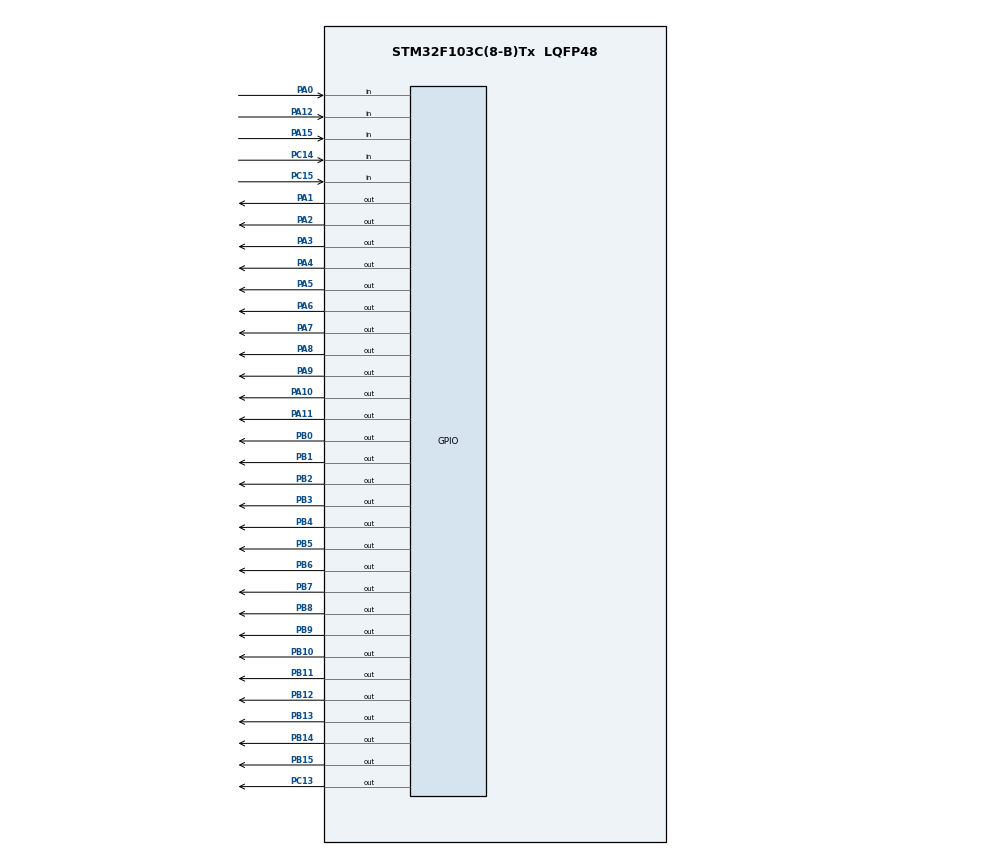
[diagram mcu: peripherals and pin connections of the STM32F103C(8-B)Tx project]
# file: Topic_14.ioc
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Mcu.Family=STM32F1
Mcu.Name=STM32F103C(8-B)Tx
Mcu.Package=LQFP48
NVIC.PriorityGroup=NVIC_PRIORITYGROUP_4
PA0-WKUP.GPIO_PuPd=GPIO_PULLUP
PA0-WKUP.Signal=GPIO_Input
PA1.Signal=GPIO_Output
PA10.Signal=GPIO_Output
PA11.Signal=GPIO_Output
PA12.GPIO_PuPd=GPIO_PULLUP
PA12.Signal=GPIO_Input
PA13.Mode=Serial_Wire
PA13.Signal=SYS_JTMS-SWDIO
PA14.Mode=Serial_Wire
PA14.Signal=SYS_JTCK-SWCLK
PA15.GPIO_PuPd=GPIO_PULLUP
PA15.Signal=GPIO_Input
PA2.Signal=GPIO_Output
PA3.Signal=GPIO_Output
PA4.Signal=GPIO_Output
PA5.Signal=GPIO_Output
PA6.Signal=GPIO_Output
PA7.Signal=GPIO_Output
PA8.Signal=GPIO_Output
PA9.Signal=GPIO_Output
PB0.Signal=GPIO_Output
PB1.Signal=GPIO_Output
PB10.Signal=GPIO_Output
PB11.Signal=GPIO_Output
PB12.GPIO_PuPd=GPIO_NOPULL
PB12.Signal=GPIO_Output
PB13.Signal=GPIO_Output
PB14.Signal=GPIO_Output
PB15.GPIO_PuPd=GPIO_NOPULL
PB15.Signal=GPIO_Output
PB2.Signal=GPIO_Output
PB3.Signal=GPIO_Output
PB4.Signal=GPIO_Output
PB5.Signal=GPIO_Output
PB6.Signal=GPIO_Output
PB7.Signal=GPIO_Output
PB8.Signal=GPIO_Output
PB9.Signal=GPIO_Output
PC13-TAMPER-RTC.Signal=GPIO_Output
PC14-OSC32_IN.GPIO_PuPd=GPIO_PULLUP
PC14-OSC32_IN.Signal=GPIO_Input
PC15-OSC32_OUT.GPIO_PuPd=GPIO_PULLUP
PC15-OSC32_OUT.Signal=GPIO_Input
ProjectManager.HeapSize=0x200
ProjectManager.StackSize=0x400
ProjectManager.TargetToolchain=Other Toolchains (GPDSC)
RCC.APB1Freq_Value=8000000
RCC.APB2Freq_Value=8000000
board=custom

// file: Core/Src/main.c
/* USER CODE BEGIN Header */
/**
  ******************************************************************************
  * @file           : main.c
  * @brief          : Main program body
  ******************************************************************************
  * @attention
  *
  * <h2><center>&copy; Copyright (c) 2025 STMicroelectronics.
  * All rights reserved.</center></h2>
  *
  * This software component is licensed by ST under BSD 3-Clause license,
  * the "License"; You may not use this file except in compliance with the
  * License. You may obtain a copy of the License at:
  *                        opensource.org/licenses/BSD-3-Clause
  *
  ******************************************************************************
  */
/* USER CODE END Header */
#include "main.h"

void SystemClock_Config(void);
static void MX_GPIO_Init(void);

int main(void)
{

	/* MCU Configuration--------------------------------------------------------*/

	/* Reset of all peripherals, Initializes the Flash interface and the Systick. */
	HAL_Init();

	/* Configure the system clock */
	SystemClock_Config();

	/* Initialize all configured peripherals */
	MX_GPIO_Init();

	/* USER CODE BEGIN 2 */

	test(50); //Самоиндикация экрана

	Test_4_LED(50); //Самоиндикация 4 лампочек

	Test_12_LED(50); //Самоиндикация 12 лампочек

	// Число для помощи формирования 2-чного
	int64_t countNums = 0;
	// Число в 2-чном представление
	uint64_t binaryNums = 0;

	// 1-ый бит измененый
	uint8_t firstBit = 0;
	// 2-ой бит измененый
	uint8_t secondBit = 0;
	// 3-ий бит измененый
	uint8_t thirdBit = 0;
	// 4-ий бит измененый
	uint8_t fourthBit = 0;

	//Первое число в 16 ричном формате
	uint8_t firstNum = 0;
	//Второе число в 16 ричном формате
	uint8_t secondNum = 0;
	//Третье число в 16 ричном формате
	uint8_t thirdNum = 0;

	int time = 0; // Переменная для подсчёта времени удержания кнопки
	int mode = 0; // Режим работы: 0 - увеличение числа, 1 - уменьшение

	/* USER CODE END 2 */

	/* Infinite loop */
	/* USER CODE BEGIN WHILE */

	  // 1 отпущина 0 нажата
	while (1)
	{

		/* USER CODE END WHILE */

		print_number(&firstNum, &secondNum, &thirdNum);
		// Преобразования числа в три шестнадцатеричных разряда
		DecimalHexadecimal(countNums, &firstNum, &secondNum, &thirdNum);
		if (countNums == 999) {

			binaryNums = 111111111111;
		}
		// Обработка удержания кнопки BUTTON_0 для смены режима
		if (HAL_GPIO_ReadPin(GPIOA, BUTTON_0) == 0) {
			DecimalHexadecimal(countNums, &firstNum, &secondNum, &thirdNum);

			time = 0;
			while (HAL_GPIO_ReadPin(GPIOA, BUTTON_0) == 0) {
				print_number(&firstNum, &secondNum, &thirdNum);
				HAL_Delay(15); // Задержка для измерения времени удержания
				time++;
			}

			if (time * 20 > 2000) {

				// Если кнопка удерживалась более 2000 мс
				mode++;
				if (mode > 2) mode = 0;

				// Сброс битов при переходе в режим 2
				if (mode == 2) {
					firstBit = 0;
					secondBit = 0;
					thirdBit = 0;
					fourthBit = 0;
				}
			}
			else {
				// Короткое нажатие - обработка в зависимости от режима
				if (mode == 0) {
					// Режим 0: увеличение
					if (countNums >= 999)
						countNums = 0;
					else
						countNums++;
					SetBinNumber(&countNums, &binaryNums);
				}
				else if (mode == 1) {
					// Режим 1: уменьшение
					if (countNums <= 0)
						countNums = 999;
					else
						countNums--;

					SetBinNumber(&countNums, &binaryNums);
				}
				// В режиме 2 короткое нажатие BUTTON_0 не делает ничего
			}
		}

		// Обработка режима 2
		if (mode == 2) {

			// Вывод числа на экран
			print_number(&firstNum, &secondNum, &thirdNum);

			// Задаем 1 бит и зажигаем 1 лампачку с помощью BUTTON_1
			SetFirstBit(&firstBit);

			// Задаем 2 бит и зажигаем 2 лампачку с помощью BUTTON_2
			SetSeconsBit(&secondBit);

			// Задаем 3 бит и зажигаем 3 лампачку с помощью BUTTON_3
			SetThirdBit(&thirdBit);

			// Задаем 4 бит и зажигаем 4 лампачку с помощью BUTTON_4
			SetFourthBit(&fourthBit);

			if (HAL_GPIO_ReadPin(GPIOA, BUTTON_0) == 0)
			{
				HAL_Delay(5);

				if (HAL_GPIO_ReadPin(GPIOA, BUTTON_0) == 0)
				{
					HAL_Delay(5);
					//Гасим светодиоды
					HAL_GPIO_WritePin(GPIOB, S_0_1, GPIO_PIN_RESET);
					HAL_GPIO_WritePin(GPIOB, S_0_2, GPIO_PIN_RESET);
					HAL_GPIO_WritePin(GPIOB, S_0_3, GPIO_PIN_RESET);
					HAL_GPIO_WritePin(GPIOC, S_0_4, GPIO_PIN_RESET);

					// Формируем 4-битное число из заданных битов
					uint64_t newBits = (firstBit << 3) | (secondBit << 2) | (thirdBit << 1) | fourthBit;

					// Сдвигаем исходное число на 4 бита влево и добавляем новые биты  числу
					countNums = (countNums << 4) | newBits;

					//Формируем в переменную binaryNums битную последовательность
					SetBinNumber(&countNums, &binaryNums);

					//Обнуляем заданные биты
					firstBit = 0;
					secondBit = 0;
					thirdBit = 0;
					fourthBit = 0;

					//Обновляем число в зависеммости от 2-чного
					countNums = Binary_to_Decimal(&binaryNums);

					// Преобразования числа в три шестнадцатеричных разряда
					DecimalHexadecimal(countNums, &firstNum, &secondNum, &thirdNum);

					// Если число больше чем 0xFFF то сбрасываем значение до 0
					if (binaryNums > 111111111111)
					{
						countNums = 0;
						binaryNums = 0;
						firstNum = 0;
						secondNum = 0;
						thirdNum = 0;

					}
					//Вывод числа на экран
					print_number(&firstNum, &secondNum, &thirdNum);

				}

			}
		}

			countNums = Binary_to_Decimal(&binaryNums);
			//Зажигаем 12 лампочек в зависеммости от заданого бинарного числа
			Set_LED_12_Bit(binaryNums);
			//Вывод числа на экран в 10-чном виде
			print_number(&firstNum, &secondNum, &thirdNum);

	}
}

void SystemClock_Config(void)
{
  RCC_OscInitTypeDef RCC_OscInitStruct = {0};
  RCC_ClkInitTypeDef RCC_ClkInitStruct = {0};

  /** Initializes the RCC Oscillators according to the specified parameters
  * in the RCC_OscInitTypeDef structure.
  */
  RCC_OscInitStruct.OscillatorType = RCC_OSCILLATORTYPE_HSI;
  RCC_OscInitStruct.HSIState = RCC_HSI_ON;
  RCC_OscInitStruct.HSICalibrationValue = RCC_HSICALIBRATION_DEFAULT;
  RCC_OscInitStruct.PLL.PLLState = RCC_PLL_NONE;
  if (HAL_RCC_OscConfig(&RCC_OscInitStruct) != HAL_OK)
  {
    Error_Handler();
  }
  /** Initializes the CPU, AHB and APB buses clocks
  */
  RCC_ClkInitStruct.ClockType = RCC_CLOCKTYPE_HCLK|RCC_CLOCKTYPE_SYSCLK
                              |RCC_CLOCKTYPE_PCLK1|RCC_CLOCKTYPE_PCLK2;
  RCC_ClkInitStruct.SYSCLKSource = RCC_SYSCLKSOURCE_HSI;
  RCC_ClkInitStruct.AHBCLKDivider = RCC_SYSCLK_DIV1;
  RCC_ClkInitStruct.APB1CLKDivider = RCC_HCLK_DIV1;
  RCC_ClkInitStruct.APB2CLKDivider = RCC_HCLK_DIV1;

  if (HAL_RCC_ClockConfig(&RCC_ClkInitStruct, FLASH_LATENCY_0) != HAL_OK)
  {
    Error_Handler();
  }
}

static void MX_GPIO_Init(void)
{
  GPIO_InitTypeDef GPIO_InitStruct = {0};

  /* GPIO Ports Clock Enable */
  __HAL_RCC_GPIOC_CLK_ENABLE();
  __HAL_RCC_GPIOA_CLK_ENABLE();
  __HAL_RCC_GPIOB_CLK_ENABLE();

  /*Configure GPIO pin Output Level */
  HAL_GPIO_WritePin(GPIOC, GPIO_PIN_13, GPIO_PIN_RESET);

  /*Configure GPIO pin Output Level */
  HAL_GPIO_WritePin(GPIOA, GPIO_PIN_1|GPIO_PIN_2|GPIO_PIN_3|GPIO_PIN_4
                          |GPIO_PIN_5|GPIO_PIN_6|GPIO_PIN_7|GPIO_PIN_8
                          |GPIO_PIN_9|GPIO_PIN_10|GPIO_PIN_11, GPIO_PIN_RESET);

  /*Configure GPIO pin Output Level */
  HAL_GPIO_WritePin(GPIOB, GPIO_PIN_0|GPIO_PIN_1|GPIO_PIN_2|GPIO_PIN_10
                          |GPIO_PIN_11|GPIO_PIN_12|GPIO_PIN_13|GPIO_PIN_14
                          |GPIO_PIN_15|GPIO_PIN_3|GPIO_PIN_4|GPIO_PIN_5
                          |GPIO_PIN_6|GPIO_PIN_7|GPIO_PIN_8|GPIO_PIN_9, GPIO_PIN_RESET);

  /*Configure GPIO pin : PC13 */
  GPIO_InitStruct.Pin = GPIO_PIN_13;
  GPIO_InitStruct.Mode = GPIO_MODE_OUTPUT_PP;
  GPIO_InitStruct.Pull = GPIO_NOPULL;
  GPIO_InitStruct.Speed = GPIO_SPEED_FREQ_LOW;
  HAL_GPIO_Init(GPIOC, &GPIO_InitStruct);

  /*Configure GPIO pins : PC14 PC15 */
  GPIO_InitStruct.Pin = GPIO_PIN_14|GPIO_PIN_15;
  GPIO_InitStruct.Mode = GPIO_MODE_INPUT;
  GPIO_InitStruct.Pull = GPIO_PULLUP;
  HAL_GPIO_Init(GPIOC, &GPIO_InitStruct);

  /*Configure GPIO pins : PA0 PA12 PA15 */
  GPIO_InitStruct.Pin = GPIO_PIN_0|GPIO_PIN_12|GPIO_PIN_15;
  GPIO_InitStruct.Mode = GPIO_MODE_INPUT;
  GPIO_InitStruct.Pull = GPIO_PULLUP;
  HAL_GPIO_Init(GPIOA, &GPIO_InitStruct);

  /*Configure GPIO pins : PA1 PA2 PA3 PA4
                           PA5 PA6 PA7 PA8
                           PA9 PA10 PA11 */
  GPIO_InitStruct.Pin = GPIO_PIN_1|GPIO_PIN_2|GPIO_PIN_3|GPIO_PIN_4
                          |GPIO_PIN_5|GPIO_PIN_6|GPIO_PIN_7|GPIO_PIN_8
                          |GPIO_PIN_9|GPIO_PIN_10|GPIO_PIN_11;
  GPIO_InitStruct.Mode = GPIO_MODE_OUTPUT_PP;
  GPIO_InitStruct.Pull = GPIO_NOPULL;
  GPIO_InitStruct.Speed = GPIO_SPEED_FREQ_LOW;
  HAL_GPIO_Init(GPIOA, &GPIO_InitStruct);

  /*Configure GPIO pins : PB0 PB1 PB2 PB10
                           PB11 PB12 PB13 PB14
                           PB15 PB3 PB4 PB5
                           PB6 PB7 PB8 PB9 */
  GPIO_InitStruct.Pin = GPIO_PIN_0|GPIO_PIN_1|GPIO_PIN_2|GPIO_PIN_10
                          |GPIO_PIN_11|GPIO_PIN_12|GPIO_PIN_13|GPIO_PIN_14
                          |GPIO_PIN_15|GPIO_PIN_3|GPIO_PIN_4|GPIO_PIN_5
                          |GPIO_PIN_6|GPIO_PIN_7|GPIO_PIN_8|GPIO_PIN_9;
  GPIO_InitStruct.Mode = GPIO_MODE_OUTPUT_PP;
  GPIO_InitStruct.Pull = GPIO_NOPULL;
  GPIO_InitStruct.Speed = GPIO_SPEED_FREQ_LOW;
  HAL_GPIO_Init(GPIOB, &GPIO_InitStruct);

}

void Error_Handler(void)
{
  __disable_irq();
  while (1)
  {
  }
}

/************************ (C) COPYRIGHT STMicroelectronics *****END OF FILE****/
